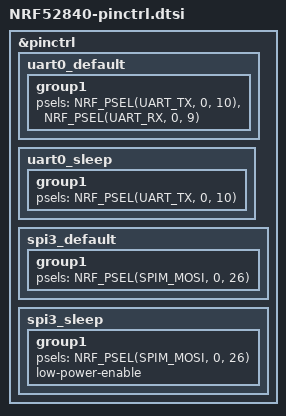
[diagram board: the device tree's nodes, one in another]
&pinctrl {
  uart0_default: uart0_default {
    group1 {
      psels = <NRF_PSEL(UART_TX, 0, 10)>, <NRF_PSEL(UART_RX, 0, 9)>;
    };
  };

  uart0_sleep: uart0_sleep {
    group1 {
      psels = <NRF_PSEL(UART_TX, 0, 10)>;
    };
  };

  /* ws2812(네오픽셀) — SPIM MOSI 만 쓴다. wish60 회로: P0.26 */
  spi3_default: spi3_default {
    group1 {
      psels = <NRF_PSEL(SPIM_MOSI, 0, 26)>;
    };
  };

  spi3_sleep: spi3_sleep {
    group1 {
      psels = <NRF_PSEL(SPIM_MOSI, 0, 26)>;
      low-power-enable;
    };
  };
};
